# f28004x_dac_regs register map
Vendor: Texas Instruments
Peripheral module from a debugger description file (folder C2000).
Address unit: 16 bits
Registers are 16-bit, read-write, no defined reset value unless marked. A register's access mark holds for its fields unless they carry their own. Offsets are as the file gives them; lines under a group give offsets from that group; [hi:lo] are bit positions; {n}, {i} and the like mark numbered series; 'fields as' and 'values as' point back to an identical list; <NAME> marks a mode.

## DAC_REGS — DAC Registers
0x00 DACREV ro — DAC Revision Register
  [7:0] REV
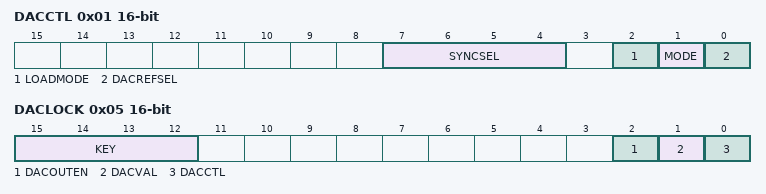
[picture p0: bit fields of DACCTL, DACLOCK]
0x01 DACCTL — DAC Control Register
  [7:4] SYNCSEL — DAC PWMSYNC Select
  [2] LOADMODE — DACVALA Load Mode
  [1] MODE — DAC Mode Select
  [0] DACREFSEL — DAC Reference Select
0x02 DACVALA ro — DAC Value Register - Active
  [11:0] DACVALA — DAC Active Output Code
0x03 DACVALS — DAC Value Register - Shadow
  [11:0] DACVALS — DAC Shadow Output Code
0x04 DACOUTEN — DAC Output Enable Register
  [0] DACOUTEN — DAC Output Code
0x05 DACLOCK access not given
  [15:12] KEY — DAC Register Lock Key (access R=0/W)
  [2] DACOUTEN — DAC Output Enable Register Lock (access R/SOnce)
  [1] DACVAL — DAC Value Register Lock (access R/SOnce)
  [0] DACCTL — DAC Control Register Lock (access R/SOnce)
0x06 DACTRIM
  [7:0] OFFSET_TRIM — DAC Offset Trim
